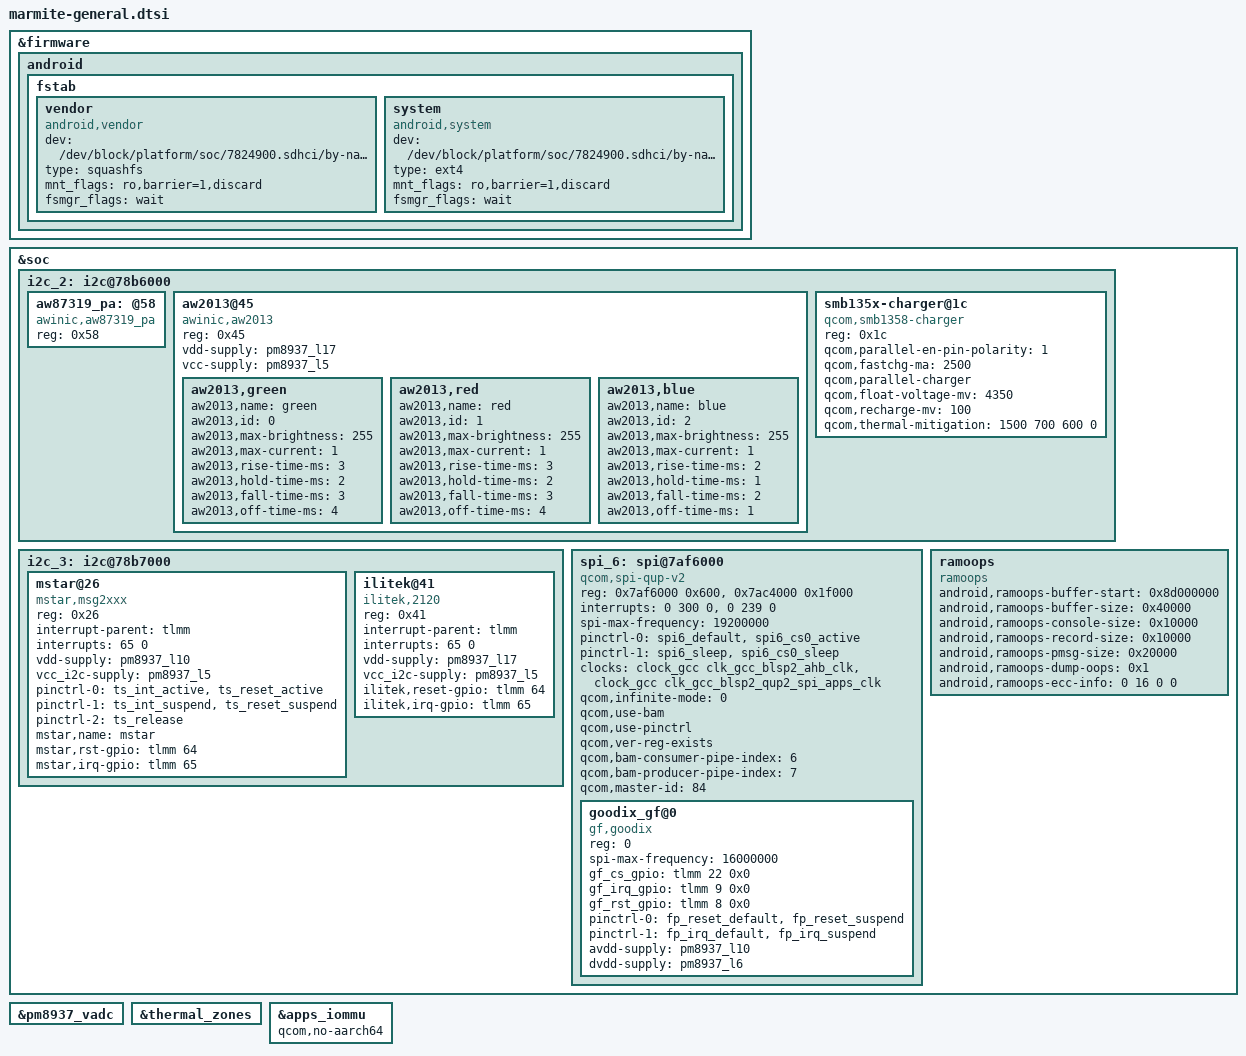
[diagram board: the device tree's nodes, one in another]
/* Copyright (c) 2020, The Linux Foundation. All rights reserved.
*  Copyright (c) 2020, Jebaitedneko.
*
* This program is free software; you can redistribute it and/or modify
* it under the terms of the GNU General Public License version 2 and
* only version 2 as published by the Free Software Foundation.
*
* This program is distributed in the hope that it will be useful,
* but WITHOUT ANY WARRANTY; without even the implied warranty of
* MERCHANTABILITY or FITNESS FOR A PARTICULAR PURPOSE.  See the
* GNU General Public License for more details.
*/

&firmware {
	android {
		/delete-node/ vbmeta;
		fstab {
			vendor {
				compatible = "android,vendor";
				dev = "/dev/block/platform/soc/7824900.sdhci/by-name/oem";
				type = "squashfs";
				mnt_flags = "ro,barrier=1,discard";
				fsmgr_flags = "wait";
				status = "ok";
			};
			system {
				compatible = "android,system";
				dev = "/dev/block/platform/soc/7824900.sdhci/by-name/system";
				type = "ext4";
				mnt_flags = "ro,barrier=1,discard";
				fsmgr_flags = "wait";
				status = "ok";
			};
		};
	};
};

&soc {

	i2c_2: i2c@78b6000 {
	
		aw87319_pa:@58 {
			compatible = "awinic,aw87319_pa";
			reg = <0x58>;
		};
		aw2013@45 {
			compatible = "awinic,aw2013";
			reg = <0x45>;
			vdd-supply = <&pm8937_l17>;
			vcc-supply = <&pm8937_l5>;

			aw2013,green {
				aw2013,name = "green";
				aw2013,id = <0>;
				aw2013,max-brightness = <255>;
				aw2013,max-current = <1>;
				aw2013,rise-time-ms = <3>;
				aw2013,hold-time-ms = <2>;
				aw2013,fall-time-ms = <3>;
				aw2013,off-time-ms = <4>;
			};

			aw2013,red {
				aw2013,name = "red";
				aw2013,id = <1>;
				aw2013,max-brightness = <255>;
				aw2013,max-current = <1>;
				aw2013,rise-time-ms = <3>;
				aw2013,hold-time-ms = <2>;
				aw2013,fall-time-ms = <3>;
				aw2013,off-time-ms = <4>;
			};
			aw2013,blue {
				aw2013,name = "blue";
				aw2013,id = <2>;
				aw2013,max-brightness = <255>;
				aw2013,max-current = <1>;
				aw2013,rise-time-ms = <2>;
				aw2013,hold-time-ms = <1>;
				aw2013,fall-time-ms = <2>;
				aw2013,off-time-ms = <1>;
			};
		};
		/* Parallel-charger configuration */
		smb135x-charger@1c {
			compatible = "qcom,smb1358-charger";
			reg = <0x1c>;
			qcom,parallel-en-pin-polarity = <1>;
			qcom,fastchg-ma = <2500>;
			qcom,parallel-charger;
			qcom,float-voltage-mv = <4350>;
			qcom,recharge-mv = <100>;
			qcom,thermal-mitigation = <1500 700 600 0>;
		};
	
	};

	i2c_3: i2c@78b7000 {

		status = "ok";
		
		mstar@26 {
			compatible = "mstar,msg2xxx";
			reg = <0x26>;
			interrupt-parent = <&tlmm>;
			interrupts = <65 0>;
			vdd-supply = <&pm8937_l10>;
			vcc_i2c-supply = <&pm8937_l5>;
			pinctrl-names = "pmx_ts_active","pmx_ts_suspend",
			"pmx_ts_release";
			pinctrl-0 = <&ts_int_active &ts_reset_active>;
			pinctrl-1 = <&ts_int_suspend &ts_reset_suspend>;
			pinctrl-2 = <&ts_release>;
			mstar,name ="mstar";
			mstar,rst-gpio = <&tlmm 64 0x0>;
			mstar,irq-gpio = <&tlmm 65 0x0>;

		};

		ilitek@41 {
			compatible = "ilitek,2120";
			reg = <0x41>;
			interrupt-parent = <&tlmm>;
			interrupts = <65 0>;
			vdd-supply = <&pm8937_l17>;
			vcc_i2c-supply = <&pm8937_l5>;
			ilitek,reset-gpio = <&tlmm 64 0x0>;
			ilitek,irq-gpio = <&tlmm 65 0x0>;
		};
	
	};

	spi_6: spi@7af6000 { /* BLSP2 QUP2 */
	        compatible = "qcom,spi-qup-v2";
	        #address-cells = <1>;
	        #size-cells = <0>;
	        reg-names = "spi_physical", "spi_bam_physical";
	        reg = <0x7af6000 0x600>,
	                <0x7ac4000 0x1f000>;
	        interrupt-names = "spi_irq", "spi_bam_irq";
	        interrupts = <0 300 0>, <0 239 0>;
	        spi-max-frequency = <19200000>;
	        pinctrl-names = "spi_default", "spi_sleep";
	        pinctrl-0 = <&spi6_default &spi6_cs0_active>;
	        pinctrl-1 = <&spi6_sleep &spi6_cs0_sleep>;
	        clocks = <&clock_gcc clk_gcc_blsp2_ahb_clk>,
	                <&clock_gcc clk_gcc_blsp2_qup2_spi_apps_clk>;
	        clock-names = "iface_clk", "core_clk";
	        qcom,infinite-mode = <0>;
	        qcom,use-bam;
	        qcom,use-pinctrl;
	        qcom,ver-reg-exists;
	        qcom,bam-consumer-pipe-index = <6>;
	        qcom,bam-producer-pipe-index = <7>;
	        qcom,master-id = <84>;
	        status = "ok"; 

		goodix_gf@0 {
	        	status = "ok";
	        	compatible = "gf,goodix";
	        	reg = <0>;
	        	pinctrl-names = "fp_active","fp_suspend";
	        	spi-max-frequency = <16000000>;
	        	gf_cs_gpio = <&tlmm 22 0x0>;
	        	gf_irq_gpio = <&tlmm 9 0x0>;
	        	gf_rst_gpio = <&tlmm 8 0x0>;
	        	pinctrl-0 = <&fp_reset_default &fp_reset_suspend>;
	        	pinctrl-1 = <&fp_irq_default &fp_irq_suspend>;
	        	avdd-supply = <&pm8937_l10>;
	        	dvdd-supply = <&pm8937_l6>;
		};

	};

	ramoops {
	        compatible = "ramoops";
	        status = "okay";

	        android,ramoops-buffer-start = <0x8d000000>;
	        android,ramoops-buffer-size =  <0x40000>;
	        android,ramoops-console-size = <0x10000>;
	        android,ramoops-record-size = <0x10000>;
	        android,ramoops-pmsg-size = <0x20000>;
	        android,ramoops-dump-oops = <0x1>;
	        android,ramoops-ecc-info = <0 16 0 0>; /* < block_size, ecc_size, sym_size, poly >, only ecc_size will suffice to enable ecc */
	};
};

&pm8937_vadc {
	/delete-node/ chan@11;
};

&thermal_zones {
	/delete-node/ pa-therm1-adc;
};

&apps_iommu {
	qcom,no-aarch64;
};
